# DEBUGSS_WRAP_CFGAP_CFG_1_000740002000h register map
Vendor: Texas Instruments
Peripheral module from a debugger description file (folder am62D).
Registers are 32-bit, read-only, reset values left out (the file's numbers can be read two ways) unless marked. A register's access mark holds for its fields unless they carry their own. Offsets are as the file gives them; lines under a group give offsets from that group; [hi:lo] are bit positions; {n}, {i} and the like mark numbered series; 'fields as' and 'values as' point back to an identical list; <NAME> marks a mode.

## cfgap_cfg_1
0x00 cfgap_cfg_1_JTAGID_REG — This register returns the JTAG ID tieoff of the device. The reset value depends on the tie off
  [31:0] JTAG_ID — The JTAG ID of the device
0x04 cfgap_cfg_1_USERID_REG — This register returns the Chip Spin ID tieoff value of the device. The reset value depends on the tieoff
  [31:0] USER_ID — The USER ID of the device
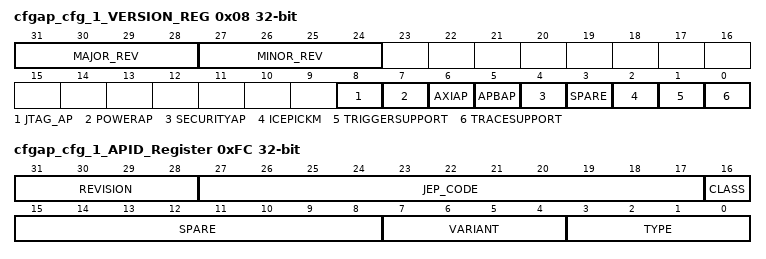
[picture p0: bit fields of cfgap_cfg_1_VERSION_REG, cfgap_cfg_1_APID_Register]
0x08 cfgap_cfg_1_VERSION_REG — This register is used to read the RTL version information and to determine which modules are included in the rtl build. The reset value depends on the build options
  [31:28] MAJOR_REV — RTL Major revision [5]
  [27:24] MINOR_REV — RTL Minor revision [0]
  [8] JTAG_AP — a 1 indicates JTAG AP is supported
  [7] POWERAP — A 1 indicates that the Power AP is supported
  [6] AXIAP — A 1 indicates that the AXIAP exists and system memory accesses are supported
  [5] APBAP — A 1 indicates that the APBAP exisits and accesses to external debug logic are supported
  [4] SECURITYAP — A 1 indicates that the Security AP is supported
  [3] SPARE — This is a spare bit, returns 0
  [2] ICEPICKM — A 1 indicates that ICEPick M is present inthe design
  [1] TRIGGERSUPPORT — A 1 indicates that cross triggering is supported
  [0] TRACESUPPORT — A 1 indicates that hardware trace export is supported
0x0C cfgap_cfg_1_SYSTEMSTATUS — Reading this register returns system status information.
0xFC cfgap_cfg_1_APID_Register — Reading this register returns the ID information for this AP.
  [31:28] REVISION — Device Revision [0]
  [27:17] JEP_CODE — Device JEP Code [0x017]
  [16] CLASS — Device Class[0] [not a memory access port]
  [15:8] SPARE — Spare, returns 0
  [7:4] VARIANT — Device Variant [0]
  [3:0] TYPE — Device Type: 0=JTAG, 1=AHB, 2=APB [1]
